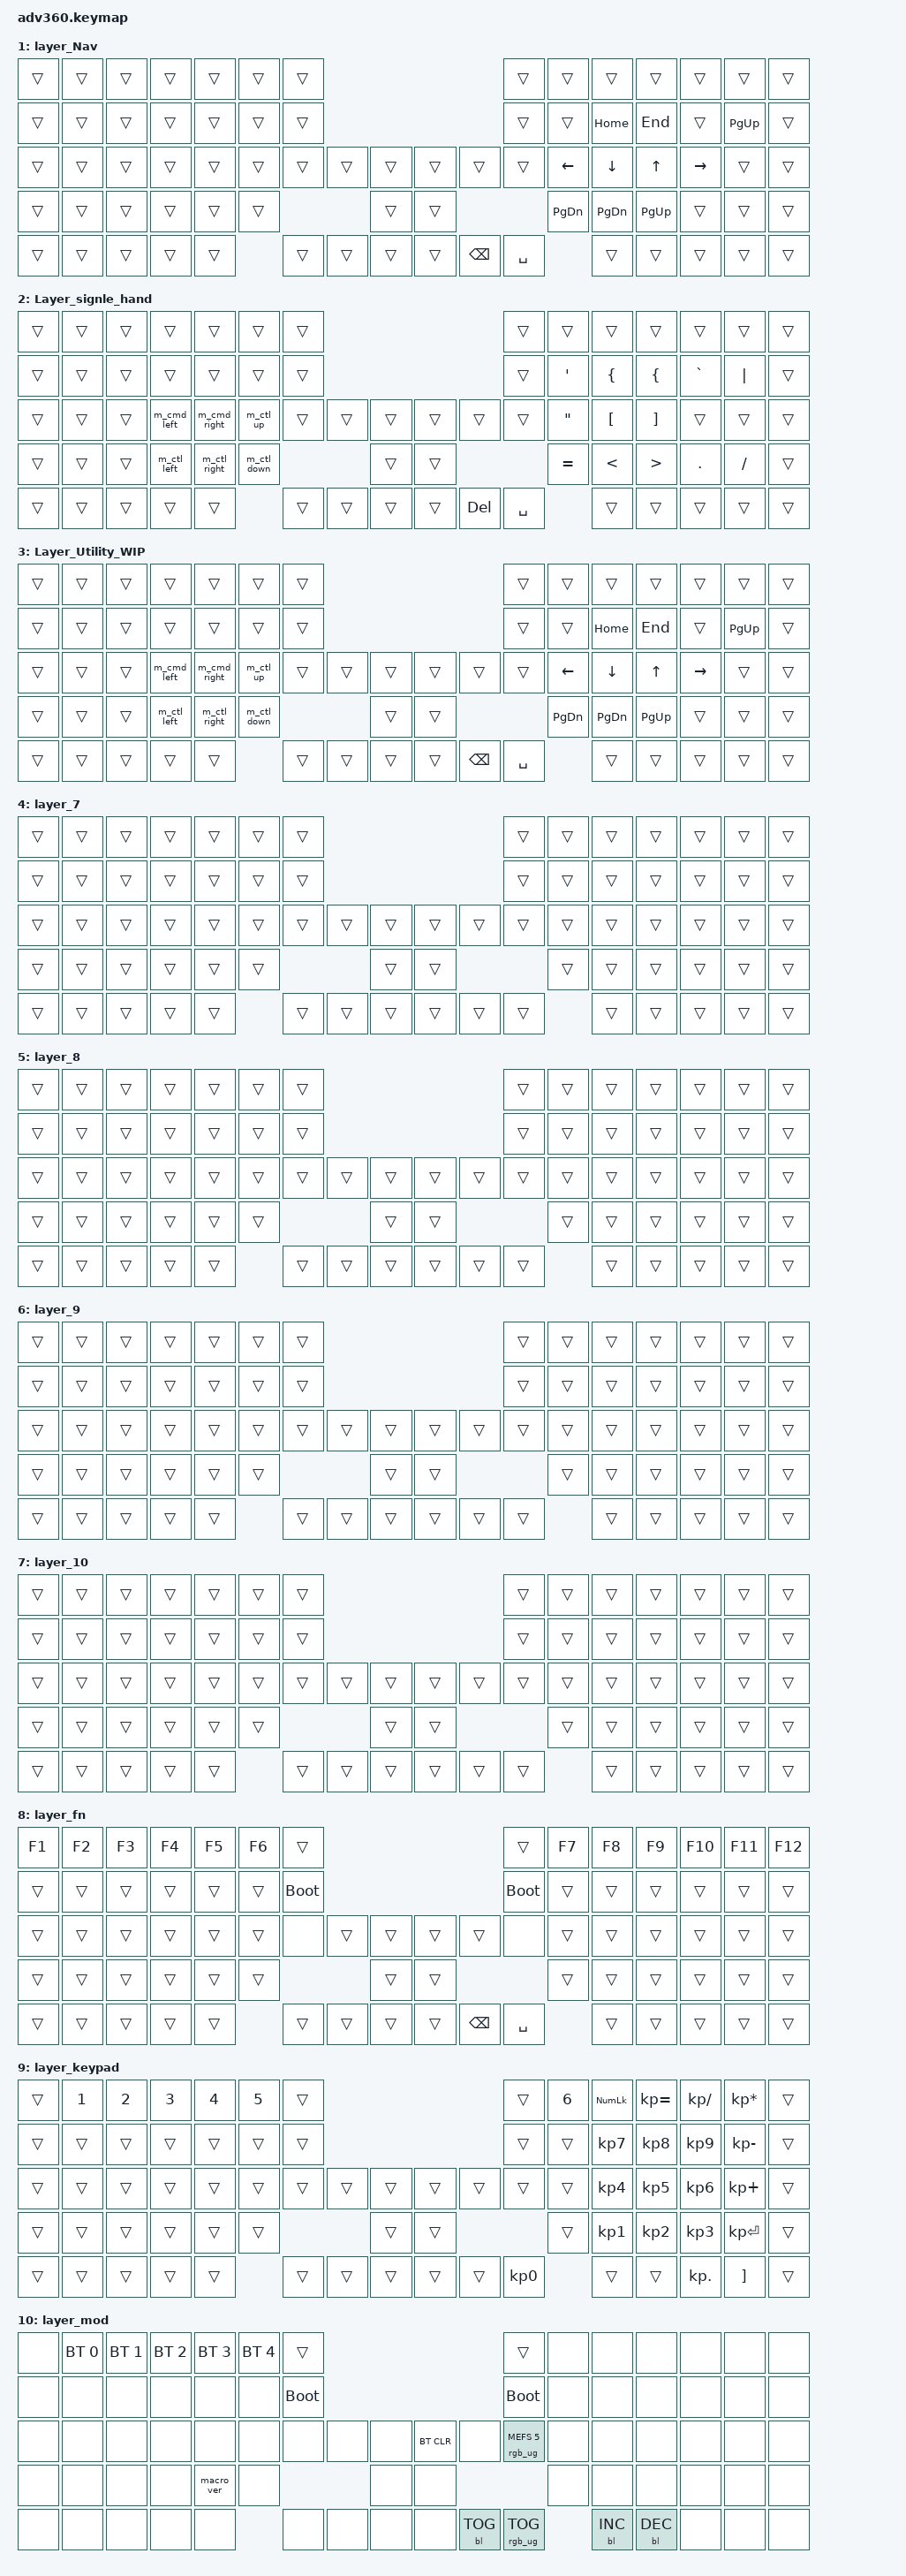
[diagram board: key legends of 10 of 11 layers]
/*
 * Copyright (c) 2020 The ZMK Contributors
 *
 * SPDX-License-Identifier: MIT
 */
/* THIS FILE WAS GENERATED!
 *
 * This file was generated automatically. You may or may not want to
 * edit it directly.
 */

#include <behaviors.dtsi>
#include <dt-bindings/zmk/backlight.h>
#include <dt-bindings/zmk/bt.h>
#include <dt-bindings/zmk/keys.h>
#include <dt-bindings/zmk/rgb.h>

&lt { quick-tap-ms = <300>; };

/ {
    behaviors {
        #include "macros.dtsi"
    #include "version.dtsi"

        hm: homerow_mods {
            compatible = "zmk,behavior-hold-tap";
            label = "HOMEROW_MODS";
            #binding-cells = <2>;
            tapping-term-ms = <200>;
            quick_tap_ms = <175>;
            flavor = "tap-preferred";
            bindings = <&kp>, <&kp>;
        };

        c_hm: custom_homerow_mods {
            compatible = "zmk,behavior-hold-tap";
            label = "CUST_HM";
            bindings = <&kp>, <&kp>;

            #binding-cells = <2>;
            tapping-term-ms = <200>;
            require-prior-idle-ms = <0>;
            flavor = "balanced";
            quick-tap-ms = <175>;
        };

        r_lt: r_lt {
            compatible = "zmk,behavior-hold-tap";
            label = "REVERT_LAYER_TOGGLE";
            #binding-cells = <2>;
            tapping-term-ms = <200>;
            bindings = <&kp>, <&sl>;

            flavor = "tap-preferred";
        };

        c_hm_l: CUSTOM_HOME_MODE_LEFT {
            compatible = "zmk,behavior-hold-tap";
            label = "CUSTOM_HOME_MODE_LEFT";
            bindings = <&kp>, <&kp>;

            #binding-cells = <2>;
            tapping-term-ms = <200>;
            require-prior-idle-ms = <0>;
            flavor = "tap-preferred";
            quick-tap-ms = <175>;
            hold-trigger-key-positions = <22 40 54 23 24 25 43 42 41 55 56 57 37 38 69 70 53 68 26 44 58 74 73 72 71 8 9 10 11 12 47 48 49 50>;
        };

        c_hm_r: CUSTOM_HOME_MODE_RIGHT {
            compatible = "zmk,behavior-hold-tap";
            label = "CUSTOM_HOME_MODE_RIGHT";
            bindings = <&kp>, <&kp>;

            #binding-cells = <2>;
            tapping-term-ms = <200>;
            require-prior-idle-ms = <0>;
            flavor = "tap-preferred";
            quick-tap-ms = <175>;
            hold-trigger-key-positions = <16 17 18 19 30 31 33 32 51 50 49 48 62 63 64 65 66 67 52 36 35 3 4 5 1 2 15 29 47 61>;
        };

        lt_left: lt_left {
            compatible = "zmk,behavior-hold-tap";
            label = "LT_LEFT";
            #binding-cells = <2>;
            hold-trigger-key-positions = <22 23 24 25 8 9 10 11 43 42 41 40 54 55 56 57 70 69 38 37 53 68>;
            flavor = "tap-preferred";
            tapping-term-ms = <200>;
            bindings = <&mo>, <&kp>;
        };
    };

    combos {
        compatible = "zmk,combos";

        cust_win_wip {
            bindings = <&kp LS(LA(LC(LG(ENTER))))>;
            key-positions = <41 42>;
            timeout-ms = <10>;
        };

        combo-switch {
            bindings = <&kp LG(TAB)>;
            key-positions = <42 43>;
            timeout-ms = <10>;
        };

        Window_Right2 {
            bindings = <&kp LC(RIGHT_ARROW)>;
            key-positions = <63 64>;
            layers = <0>;
            timeout-ms = <10>;
        };

        Window_Left {
            bindings = <&kp LC(LEFT_ARROW)>;
            key-positions = <71 72>;
            layers = <0>;
            timeout-ms = <10>;
        };

        Window_Right {
            bindings = <&kp LC(RIGHT_ARROW)>;
            key-positions = <73 74>;
            layers = <0>;
            timeout-ms = <10>;
        };
    };

    macros {
        m_cmd_left: m_cmd_left {
            compatible = "zmk,behavior-macro";
            #binding-cells = <0>;
            bindings =
                <&macro_press>,
                <&kp LEFT_COMMAND>,
                <&macro_tap>,
                <&kp LEFT_ARROW>,
                <&macro_release>,
                <&kp LEFT_COMMAND>;

            label = "M_CMD_LEFT";
        };

        m_cmd_right: m_cmd_right {
            compatible = "zmk,behavior-macro";
            #binding-cells = <0>;
            bindings =
                <&macro_press>,
                <&kp LEFT_COMMAND>,
                <&macro_tap>,
                <&kp RIGHT_ARROW>,
                <&macro_release>,
                <&kp LEFT_COMMAND>;

            label = "M_CMD_RIGHT";
        };

        m_ctl_left: m_ctl_left {
            compatible = "zmk,behavior-macro";
            #binding-cells = <0>;
            bindings =
                <&macro_press>,
                <&kp LEFT_CONTROL>,
                <&macro_tap>,
                <&kp LEFT_ARROW>,
                <&macro_release>,
                <&kp LEFT_CONTROL>;

            label = "M_CTL_LEFT";
        };

        m_ctl_right: m_ctl_right {
            compatible = "zmk,behavior-macro";
            #binding-cells = <0>;
            bindings =
                <&macro_press>,
                <&kp LEFT_CONTROL>,
                <&macro_tap>,
                <&kp RIGHT_ARROW>,
                <&macro_release>,
                <&kp LEFT_CONTROL>;

            label = "M_CTL_RIGHT";
        };

        m_ctl_up: m_ctl_up {
            compatible = "zmk,behavior-macro";
            #binding-cells = <0>;
            bindings =
                <&macro_press>,
                <&kp LEFT_CONTROL>,
                <&macro_tap>,
                <&kp UP_ARROW>,
                <&macro_release>,
                <&kp LEFT_CONTROL>;

            label = "M_CTL_UP";
        };

        m_ctl_down: m_ctl_down {
            compatible = "zmk,behavior-macro";
            #binding-cells = <0>;
            bindings =
                <&macro_press>,
                <&kp LEFT_CONTROL>,
                <&macro_tap>,
                <&kp DOWN_ARROW>,
                <&macro_release>,
                <&kp LEFT_CONTROL>;

            label = "M_CTL_DOWN";
        };
    };

    keymap {
        compatible = "zmk,keymap";

        default_layer {
            bindings = <
&kp EQUAL                 &kp N1                          &kp N2                          &kp N3              &kp N4                  &kp N5  &mo 10                                                                                                                           &tog 9                   &kp N6  &kp N7                   &kp N8                      &kp NUMBER_9             &kp N0                   &kp MINUS
&kp TAB                   &c_hm_l LC(LS(LG(LEFT_ALT))) Q  &kp W                           &kp E               &kp R                   &kp T   &mt LS(LC(LEFT_ALT)) LG(LS(LC(NUMBER_4)))                                                                                        &kp LC(UP_ARROW)         &kp Y   &kp U                    &kp I                       &kp O                    &kp P                    &kp BSLH
&kp ESCAPE                &c_hm_l LEFT_ALT A              &c_hm_l LS(LA(LC(LEFT_GUI))) S  &kp D               &kp F                   &kp G   &mt LS(LC(LG(LEFT_ALT))) BACKSPACE         &kp LEFT_SHIFT    &kp LEFT_ALT          &kp RIGHT_CONTROL  &kp RIGHT_COMMAND          &kp DELETE               &kp H   &kp J                    &kp K                       &kp L                    &c_hm_r RIGHT_ALT SEMI   &kp SQT
&mt LEFT_CONTROL LG(TAB)  &c_hm_l LEFT_ALT Z              &c_hm_l LEFT_SHIFT X            &c_hm_l LEFT_GUI C  &c_hm_l LEFT_CONTROL V  &kp B                                                                &lt 2 HOME            &kp PG_UP                                                              &kp N   &c_hm_r RIGHT_CONTROL M  &c_hm_r LEFT_COMMAND COMMA  &c_hm_r RIGHT_SHIFT DOT  &c_hm_r RIGHT_ALT SLASH  &kp RSHFT
&mo 8                     &kp GRAVE                       &kp CAPS                        &kp UP_ARROW        &kp DOWN                        &mt LEFT_COMMAND LG(TAB)                   &lt_left 1 ENTER  &mt LEFT_ALT END      &kp PAGE_DOWN      &c_hm RIGHT_ALT BACKSPACE  &c_hm RIGHT_SHIFT SPACE          &kp LEFT_ARROW           &kp RIGHT_ARROW             &kp LBKT                 &kp RBKT                 &mo 8
            >;
        };

        layer_Nav {
            bindings = <
&trans  &trans  &trans  &trans  &trans  &trans  &trans                                             &trans     &trans         &trans         &trans       &trans     &trans       &trans
&trans  &trans  &trans  &trans  &trans  &trans  &trans                                             &trans     &trans         &kp HOME       &kp END      &trans     &kp PAGE_UP  &trans
&trans  &trans  &trans  &trans  &trans  &trans  &trans  &trans  &trans      &trans  &trans         &trans     &kp LEFT       &kp DOWN       &kp UP       &kp RIGHT  &trans       &trans
&trans  &trans  &trans  &trans  &trans  &trans                  &trans      &trans                            &kp PAGE_DOWN  &kp PAGE_DOWN  &kp PAGE_UP  &trans     &trans       &trans
&trans  &trans  &trans  &trans  &trans          &trans  &trans  &trans      &trans  &kp BACKSPACE  &kp SPACE                 &trans         &trans       &trans     &trans       &trans
            >;
        };

        Layer_signle_hand {
            bindings = <
&trans  &trans  &trans  &trans       &trans        &trans       &trans                                          &trans     &trans             &trans            &trans             &trans     &trans     &trans
&trans  &trans  &trans  &trans       &trans        &trans       &trans                                          &trans     &kp SINGLE_QUOTE   &kp LEFT_BRACE    &kp LEFT_BRACE     &kp GRAVE  &kp PIPE   &trans
&trans  &trans  &trans  &m_cmd_left  &m_cmd_right  &m_ctl_up    &trans  &trans  &trans      &trans  &trans      &trans     &kp DOUBLE_QUOTES  &kp LEFT_BRACKET  &kp RIGHT_BRACKET  &trans     &trans     &trans
&trans  &trans  &trans  &m_ctl_left  &m_ctl_right  &m_ctl_down                  &trans      &trans                         &kp EQUAL          &kp LESS_THAN     &kp GREATER_THAN   &kp DOT    &kp SLASH  &trans
&trans  &trans  &trans  &trans       &trans                     &trans  &trans  &trans      &trans  &kp DELETE  &kp SPACE                     &trans            &trans             &trans     &trans     &trans
            >;
        };

        Layer_Utility_WIP {
            bindings = <
&trans  &trans  &trans  &trans       &trans        &trans       &trans                                             &trans     &trans     &trans     &trans     &trans     &trans     &trans
&trans  &trans  &trans  &trans       &trans        &trans       &trans                                             &trans     &trans     &kp HOME   &kp END    &trans     &kp PG_UP  &trans
&trans  &trans  &trans  &m_cmd_left  &m_cmd_right  &m_ctl_up    &trans  &trans  &trans      &trans  &trans         &trans     &kp LEFT   &kp DOWN   &kp UP     &kp RIGHT  &trans     &trans
&trans  &trans  &trans  &m_ctl_left  &m_ctl_right  &m_ctl_down                  &trans      &trans                            &kp PG_DN  &kp PG_DN  &kp PG_UP  &trans     &trans     &trans
&trans  &trans  &trans  &trans       &trans                     &trans  &trans  &trans      &trans  &kp BACKSPACE  &kp SPACE             &trans     &trans     &trans     &trans     &trans
            >;
        };

        layer_7 {
            bindings = <
&trans  &trans  &trans  &trans  &trans  &trans  &trans                                      &trans  &trans  &trans  &trans  &trans  &trans  &trans
&trans  &trans  &trans  &trans  &trans  &trans  &trans                                      &trans  &trans  &trans  &trans  &trans  &trans  &trans
&trans  &trans  &trans  &trans  &trans  &trans  &trans  &trans  &trans      &trans  &trans  &trans  &trans  &trans  &trans  &trans  &trans  &trans
&trans  &trans  &trans  &trans  &trans  &trans                  &trans      &trans                  &trans  &trans  &trans  &trans  &trans  &trans
&trans  &trans  &trans  &trans  &trans          &trans  &trans  &trans      &trans  &trans  &trans          &trans  &trans  &trans  &trans  &trans
            >;
        };

        layer_8 {
            bindings = <
&trans  &trans  &trans  &trans  &trans  &trans  &trans                                      &trans  &trans  &trans  &trans  &trans  &trans  &trans
&trans  &trans  &trans  &trans  &trans  &trans  &trans                                      &trans  &trans  &trans  &trans  &trans  &trans  &trans
&trans  &trans  &trans  &trans  &trans  &trans  &trans  &trans  &trans      &trans  &trans  &trans  &trans  &trans  &trans  &trans  &trans  &trans
&trans  &trans  &trans  &trans  &trans  &trans                  &trans      &trans                  &trans  &trans  &trans  &trans  &trans  &trans
&trans  &trans  &trans  &trans  &trans          &trans  &trans  &trans      &trans  &trans  &trans          &trans  &trans  &trans  &trans  &trans
            >;
        };

        layer_9 {
            bindings = <
&trans  &trans  &trans  &trans  &trans  &trans  &trans                                      &trans  &trans  &trans  &trans  &trans  &trans  &trans
&trans  &trans  &trans  &trans  &trans  &trans  &trans                                      &trans  &trans  &trans  &trans  &trans  &trans  &trans
&trans  &trans  &trans  &trans  &trans  &trans  &trans  &trans  &trans      &trans  &trans  &trans  &trans  &trans  &trans  &trans  &trans  &trans
&trans  &trans  &trans  &trans  &trans  &trans                  &trans      &trans                  &trans  &trans  &trans  &trans  &trans  &trans
&trans  &trans  &trans  &trans  &trans          &trans  &trans  &trans      &trans  &trans  &trans          &trans  &trans  &trans  &trans  &trans
            >;
        };

        layer_10 {
            bindings = <
&trans  &trans  &trans  &trans  &trans  &trans  &trans                                      &trans  &trans  &trans  &trans  &trans  &trans  &trans
&trans  &trans  &trans  &trans  &trans  &trans  &trans                                      &trans  &trans  &trans  &trans  &trans  &trans  &trans
&trans  &trans  &trans  &trans  &trans  &trans  &trans  &trans  &trans      &trans  &trans  &trans  &trans  &trans  &trans  &trans  &trans  &trans
&trans  &trans  &trans  &trans  &trans  &trans                  &trans      &trans                  &trans  &trans  &trans  &trans  &trans  &trans
&trans  &trans  &trans  &trans  &trans          &trans  &trans  &trans      &trans  &trans  &trans          &trans  &trans  &trans  &trans  &trans
            >;
        };

        layer_fn {
            bindings = <
&kp F1  &kp F2  &kp F3  &kp F4  &kp F5  &kp F6  &trans                                                  &trans       &kp F7  &kp F8  &kp F9  &kp F10  &kp F11  &kp F12
&trans  &trans  &trans  &trans  &trans  &trans  &bootloader                                             &bootloader  &trans  &trans  &trans  &trans   &trans   &trans
&trans  &trans  &trans  &trans  &trans  &trans  &none        &trans  &trans      &trans  &trans         &none        &trans  &trans  &trans  &trans   &trans   &trans
&trans  &trans  &trans  &trans  &trans  &trans                       &trans      &trans                              &trans  &trans  &trans  &trans   &trans   &trans
&trans  &trans  &trans  &trans  &trans          &trans       &trans  &trans      &trans  &kp BACKSPACE  &kp SPACE            &trans  &trans  &trans   &trans   &trans
            >;
        };

        layer_keypad {
            bindings = <
&trans  &kp N1  &kp N2  &kp N3  &kp N4  &kp N5  &trans                                      &trans     &kp N6  &kp KP_NUM  &kp KP_EQUAL  &kp KP_DIVIDE  &kp KP_MULTIPLY  &trans
&trans  &trans  &trans  &trans  &trans  &trans  &trans                                      &trans     &trans  &kp KP_N7   &kp KP_N8     &kp KP_N9      &kp KP_MINUS     &trans
&trans  &trans  &trans  &trans  &trans  &trans  &trans  &trans  &trans      &trans  &trans  &trans     &trans  &kp KP_N4   &kp KP_N5     &kp KP_N6      &kp KP_PLUS      &trans
&trans  &trans  &trans  &trans  &trans  &trans                  &trans      &trans                     &trans  &kp KP_N1   &kp KP_N2     &kp KP_N3      &kp KP_ENTER     &trans
&trans  &trans  &trans  &trans  &trans          &trans  &trans  &trans      &trans  &trans  &kp KP_N0          &trans      &trans        &kp KP_DOT     &kp RBKT         &trans
            >;
        };

        layer_mod {
            bindings = <
&none  &bt BT_SEL 0  &bt BT_SEL 1  &bt BT_SEL 2  &bt BT_SEL 3  &bt BT_SEL 4  &trans                                                 &trans                  &none  &none       &none       &none  &none  &none
&none  &none         &none         &none         &none         &none         &bootloader                                            &bootloader             &none  &none       &none       &none  &none  &none
&none  &none         &none         &none         &none         &none         &none        &none  &none      &bt BT_CLR  &none       &rgb_ug RGB_MEFS_CMD 5  &none  &none       &none       &none  &none  &none
&none  &none         &none         &none         &macro_ver    &none                             &none      &none                                           &none  &none       &none       &none  &none  &none
&none  &none         &none         &none         &none                       &none        &none  &none      &none       &bl BL_TOG  &rgb_ug RGB_TOG                &bl BL_INC  &bl BL_DEC  &none  &none  &none
            >;
        };
    };
};
